# SAM9X60 device description
Architecture: ARM926EJS; Family: SAM9; Series: SAM9X
Registers are 32-bit, read-write, no defined reset value unless marked. A register's access mark holds for its fields unless they carry their own. Offsets are from the block's base; [hi:lo] are bit positions; lines under a group give offsets from that group; {n}, {i} and the like mark numbered series; 'fields as' and 'values as' point back to an identical list.

## CAN — Controller Area Network
Instances: CAN0 0xF8000000, CAN1 0xF8004000
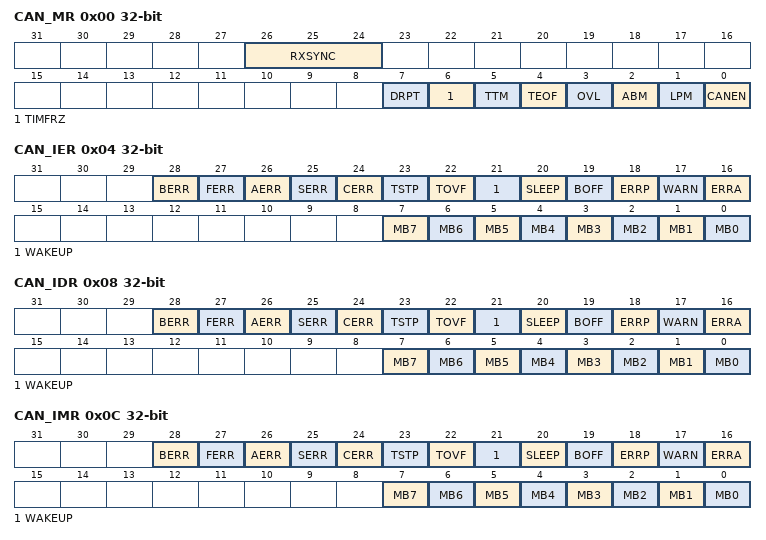
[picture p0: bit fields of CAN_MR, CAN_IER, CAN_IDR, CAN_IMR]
0x00 CAN_MR — Mode Register
  [26:24] RXSYNC — Reception Synchronization Stage (not readable)
    0=DOUBLE_PP (Rx Signal with Double Synchro Stages (2 Positive Edges)); 1=DOUBLE_PN (Rx Signal with Double Synchro Stages (One Positive Edge and One Negative Edge)); 2=SINGLE_P (Rx Signal with Single Synchro Stage (Positive Edge)); 3=NONE (Rx Signal with No Synchro Stage)
  [7] DRPT — Disable Repeat
  [6] TIMFRZ — Enable Timer Freeze
  [5] TTM — Disable/Enable Time-Triggered Mode
  [4] TEOF — Timestamp messages at each end of Frame
  [3] OVL — Disable/Enable Overload Frame
  [2] ABM — Disable/Enable Autobaud/Listen mode
  [1] LPM — Disable/Enable Low-power Mode
  [0] CANEN — CAN Controller Enable
0x04 CAN_IER wo — Interrupt Enable Register
  [28] BERR — Bit Error Interrupt Enable
  [27] FERR — Form Error Interrupt Enable
  [26] AERR — Acknowledgment Error Interrupt Enable
  [25] SERR — Stuffing Error Interrupt Enable
  [24] CERR — CRC Error Interrupt Enable
  [23] TSTP — TimeStamp Interrupt Enable
  [22] TOVF — Timer Overflow Interrupt Enable
  [21] WAKEUP — Wakeup Interrupt Enable
  [20] SLEEP — Sleep Interrupt Enable
  [19] BOFF — Bus Off Mode Interrupt Enable
  [18] ERRP — Error Passive Mode Interrupt Enable
  [17] WARN — Warning Limit Interrupt Enable
  [16] ERRA — Error Active Mode Interrupt Enable
  [n] MB{n} (n=0..7) — Mailbox {n} Interrupt Enable
0x08 CAN_IDR wo — Interrupt Disable Register
  [28] BERR — Bit Error Interrupt Disable
  [27] FERR — Form Error Interrupt Disable
  [26] AERR — Acknowledgment Error Interrupt Disable
  [25] SERR — Stuffing Error Interrupt Disable
  [24] CERR — CRC Error Interrupt Disable
  [23] TSTP — TimeStamp Interrupt Disable
  [22] TOVF — Timer Overflow Interrupt
  [21] WAKEUP — Wakeup Interrupt Disable
  [20] SLEEP — Sleep Interrupt Disable
  [19] BOFF — Bus Off Mode Interrupt Disable
  [18] ERRP — Error Passive Mode Interrupt Disable
  [17] WARN — Warning Limit Interrupt Disable
  [16] ERRA — Error Active Mode Interrupt Disable
  [n] MB{n} (n=0..7) — Mailbox {n} Interrupt Disable
0x0C CAN_IMR ro — Interrupt Mask Register
  [28] BERR — Bit Error Interrupt Mask
  [27] FERR — Form Error Interrupt Mask
  [26] AERR — Acknowledgment Error Interrupt Mask
  [25] SERR — Stuffing Error Interrupt Mask
  [24] CERR — CRC Error Interrupt Mask
  [23] TSTP — Timestamp Interrupt Mask
  [22] TOVF — Timer Overflow Interrupt Mask
  [21] WAKEUP — Wakeup Interrupt Mask
  [20] SLEEP — Sleep Interrupt Mask
  [19] BOFF — Bus Off Mode Interrupt Mask
  [18] ERRP — Error Passive Mode Interrupt Mask
  [17] WARN — Warning Limit Interrupt Mask
  [16] ERRA — Error Active Mode Interrupt Mask
  [n] MB{n} (n=0..7) — Mailbox {n} Interrupt Mask
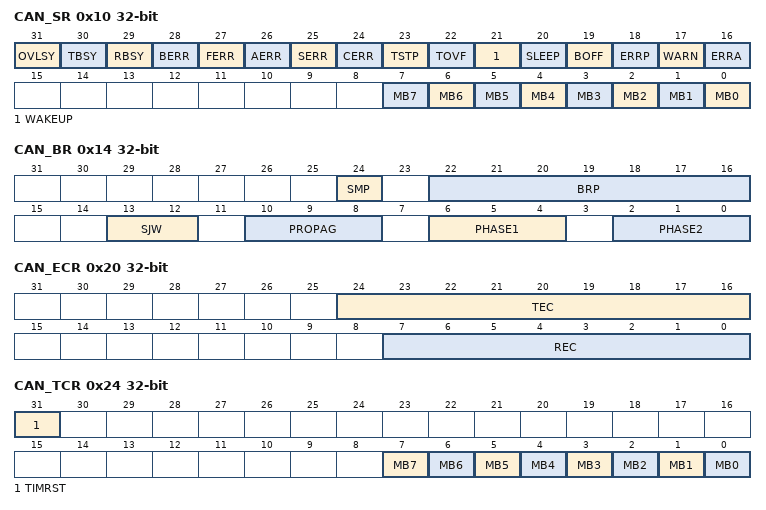
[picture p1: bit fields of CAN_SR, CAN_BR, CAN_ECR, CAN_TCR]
0x10 CAN_SR ro — Status Register
  [31] OVLSY — Overload busy
  [30] TBSY — Transmitter Busy
  [29] RBSY — Receiver Busy
  [28] BERR — Bit Error (automatically cleared by reading CAN_SR)
  [27] FERR — Form Error (automatically cleared by reading CAN_SR)
  [26] AERR — Acknowledgment Error (automatically cleared by reading CAN_SR)
  [25] SERR — Mailbox Stuffing Error (automatically cleared by reading CAN_SR)
  [24] CERR — Mailbox CRC Error (automatically cleared by reading CAN_SR)
  [23] TSTP — Timestamp (automatically cleared by reading CAN_SR)
  [22] TOVF — Timer Overflow (automatically cleared by reading CAN_SR)
  [21] WAKEUP — CAN Controller is not in Low-power Mode
  [20] SLEEP — CAN Controller in Low-power Mode
  [19] BOFF — Bus Off Mode (automatically cleared by reading CAN_SR)
  [18] ERRP — Error Passive Mode (automatically cleared by reading CAN_SR)
  [17] WARN — Warning Limit (automatically cleared by reading CAN_SR)
  [16] ERRA — Error Active Mode (automatically cleared by reading CAN_SR)
  [n] MB{n} (n=0..7) — Mailbox {n} Event
0x14 CAN_BR — Baudrate Register
  [24] SMP — Sampling Mode
    0=ONCE (The incoming bit stream is sampled once at sample point.); 1=THREE (The incoming bit stream is sampled three times with a period of a peripheral clock, centered on sample point.)
  [22:16] BRP — Baudrate Prescaler
  [13:12] SJW — Re-synchronization Jump Width
  [10:8] PROPAG — Programming Time Segment
  [6:4] PHASE1 — Phase 1 Segment
  [2:0] PHASE2 — Phase 2 Segment
0x18 CAN_TIM ro — Timer Register
  [15:0] TIMER
0x1C CAN_TIMESTP ro — Timestamp Register
  [15:0] MTIMESTAMP — Timestamp
0x20 CAN_ECR ro — Error Counter Register
  [24:16] TEC — Transmit Error Counter
  [7:0] REC — Receive Error Counter
0x24 CAN_TCR wo — Transfer Command Register
  [31] TIMRST — Timer Reset
  [n] MB{n} (n=0..7) — Transfer Request for Mailbox {n}
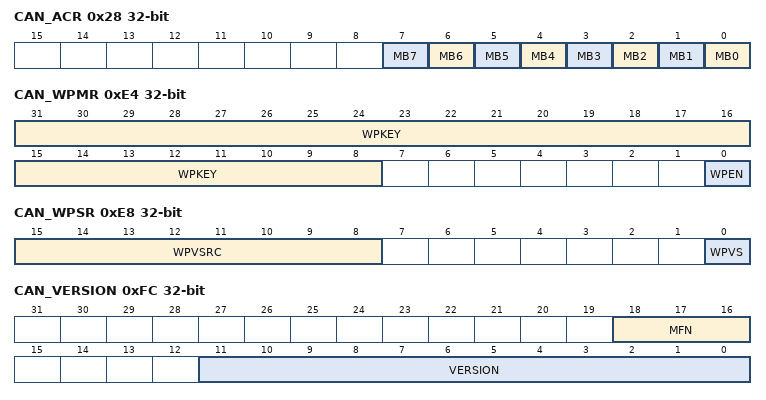
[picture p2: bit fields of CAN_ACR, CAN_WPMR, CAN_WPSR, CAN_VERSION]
0x28 CAN_ACR wo — Abort Command Register
  [n] MB{n} (n=0..7) — Abort Request for Mailbox {n}
0xE4 CAN_WPMR — Write Protection Mode Register
  [31:8] WPKEY — Write Protection Key Password
    0x43414E=PASSWD (Writing any other value in this field aborts the write operation of the WPEN bit. Always reads as 0)
  [0] WPEN — Write Protection Enable
0xE8 CAN_WPSR ro — Write Protection Status Register
  [15:8] WPVSRC — Write Protection Violation Source
  [0] WPVS — Write Protection Violation Status
0xFC CAN_VERSION ro — Version Register
  [18:16] MFN — Metal Fix Number
  [11:0] VERSION — Hardware Module Version
{0x200+0x20*i} CAN_MB[{i}] (i=0..7) group
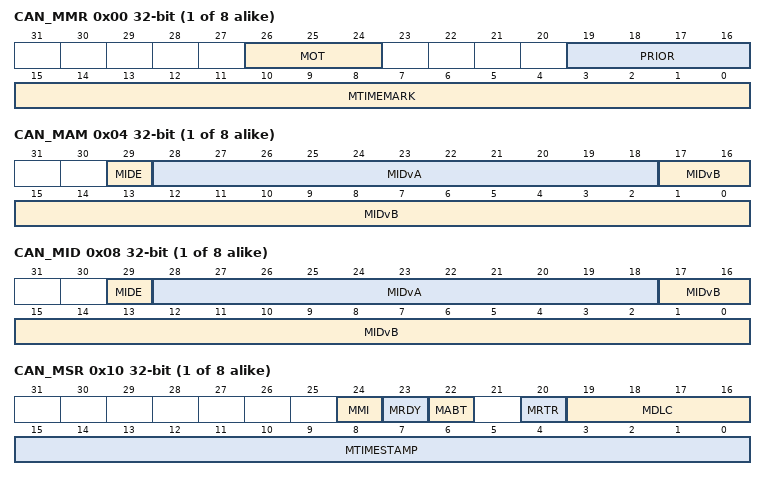
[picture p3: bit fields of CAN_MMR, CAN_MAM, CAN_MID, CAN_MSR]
  0x00 CAN_MMR — Mailbox Mode Register
    [26:24] MOT — Mailbox Object Type
      0=MB_DISABLED (Mailbox is disabled. This prevents receiving or transmitting any messages with this mailbox.); 1=MB_RX (Reception Mailbox. Mailbox is configured for reception. If a message is received while the mailbox data register is full, it is discarded.); 2=MB_RX_OVERWRITE (Reception mailbox with overwrite. Mailbox is configured for reception. If a message is received while the mailbox is full, it overwrites the previous message.); 3=MB_TX (Transmit mailbox. Mailbox is configured for transmission.); 4=MB_CONSUMER (Consumer Mailbox. Mailbox is configured in reception but behaves as a Transmit Mailbox, i.e., it sends a remote frame and waits for an answer.); 5=MB_PRODUCER (Producer Mailbox. Mailbox is configured in transmission but also behaves like a reception mailbox, i.e., it waits to receive a Remote Frame before sending its contents.)
    [19:16] PRIOR — Mailbox Priority
    [15:0] MTIMEMARK — Mailbox Timemark
  0x04 CAN_MAM — Mailbox Acceptance Mask Register
    [29] MIDE — Identifier Version
    [28:18] MIDvA — Identifier for standard frame mode
    [17:0] MIDvB — Complementary bits for identifier in extended frame mode
  0x08 CAN_MID — Mailbox ID Register
    fields as CAN_MB[0].CAN_MAM
  0x0C CAN_MFID ro — Mailbox Family ID Register
    [28:0] MFID — Family ID
  0x10 CAN_MSR ro — Mailbox Status Register
    [24] MMI — Mailbox Message Ignored (cleared by reading CAN_MSRx)
    [23] MRDY — Mailbox Ready (cleared by writing MTCR or MACR in the CAN_MCRx)
    [22] MABT — Mailbox Message Abort (cleared by writing MTCR or MACR in the CAN_MCRx)
    [20] MRTR — Mailbox Remote Transmission Request
    [19:16] MDLC — Mailbox Data Length Code
    [15:0] MTIMESTAMP — Timer Value
  0x14 CAN_MDL — Mailbox Data Low Register
    [31:0] MDL — Message Data Low Value
  0x18 CAN_MDH — Mailbox Data High Register
    [31:0] MDH — Message Data High Value
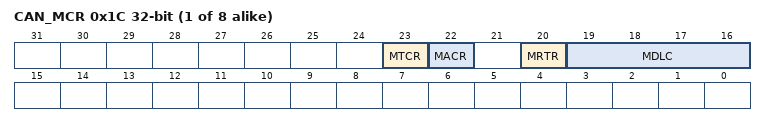
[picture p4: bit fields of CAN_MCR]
  0x1C CAN_MCR wo — Mailbox Control Register
    [23] MTCR — Mailbox Transfer Command
    [22] MACR — Abort Request for Mailbox x
    [20] MRTR — Mailbox Remote Transmission Request
    [19:16] MDLC — Mailbox Data Length Code
